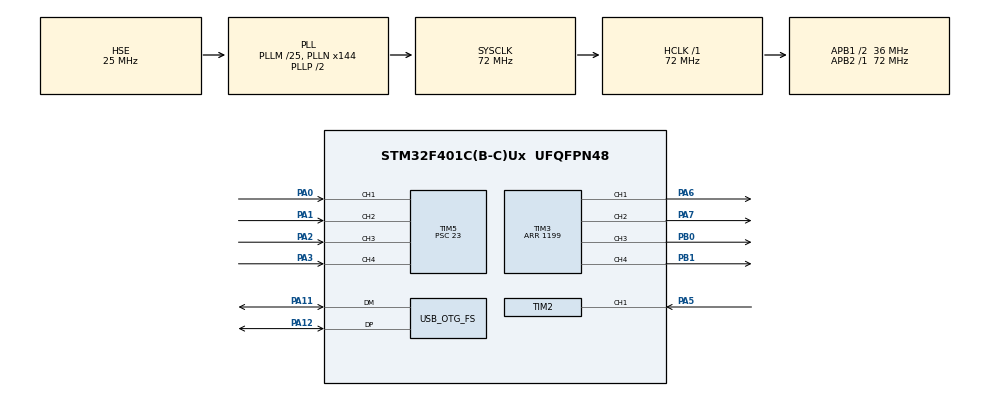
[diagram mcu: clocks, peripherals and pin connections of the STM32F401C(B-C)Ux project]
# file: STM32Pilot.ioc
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Dma.Request0=TIM2_CH1
Dma.Request1=TIM5_CH1
Dma.Request2=TIM5_CH2
Dma.Request3=TIM5_CH3/UP
Dma.Request4=TIM5_CH4/TRIG
Dma.TIM2_CH1.0.Direction=DMA_PERIPH_TO_MEMORY
Dma.TIM2_CH1.0.FIFOMode=DMA_FIFOMODE_DISABLE
Dma.TIM2_CH1.0.Instance=DMA1_Stream5
Dma.TIM2_CH1.0.MemDataAlignment=DMA_MDATAALIGN_WORD
Dma.TIM2_CH1.0.MemInc=DMA_MINC_ENABLE
Dma.TIM2_CH1.0.Mode=DMA_CIRCULAR
Dma.TIM2_CH1.0.PeriphDataAlignment=DMA_PDATAALIGN_WORD
Dma.TIM2_CH1.0.PeriphInc=DMA_PINC_DISABLE
Dma.TIM2_CH1.0.Priority=DMA_PRIORITY_LOW
Dma.TIM5_CH1.1.Direction=DMA_PERIPH_TO_MEMORY
Dma.TIM5_CH1.1.FIFOMode=DMA_FIFOMODE_DISABLE
Dma.TIM5_CH1.1.Instance=DMA1_Stream2
Dma.TIM5_CH1.1.MemDataAlignment=DMA_MDATAALIGN_WORD
Dma.TIM5_CH1.1.MemInc=DMA_MINC_ENABLE
Dma.TIM5_CH1.1.Mode=DMA_CIRCULAR
Dma.TIM5_CH1.1.PeriphDataAlignment=DMA_PDATAALIGN_WORD
Dma.TIM5_CH1.1.PeriphInc=DMA_PINC_DISABLE
Dma.TIM5_CH1.1.Priority=DMA_PRIORITY_LOW
Dma.TIM5_CH2.2.Direction=DMA_PERIPH_TO_MEMORY
Dma.TIM5_CH2.2.FIFOMode=DMA_FIFOMODE_DISABLE
Dma.TIM5_CH2.2.Instance=DMA1_Stream4
Dma.TIM5_CH2.2.MemDataAlignment=DMA_MDATAALIGN_WORD
Dma.TIM5_CH2.2.MemInc=DMA_MINC_ENABLE
Dma.TIM5_CH2.2.Mode=DMA_CIRCULAR
Dma.TIM5_CH2.2.PeriphDataAlignment=DMA_PDATAALIGN_WORD
Dma.TIM5_CH2.2.PeriphInc=DMA_PINC_DISABLE
Dma.TIM5_CH2.2.Priority=DMA_PRIORITY_LOW
Dma.TIM5_CH3/UP.3.Direction=DMA_PERIPH_TO_MEMORY
Dma.TIM5_CH3/UP.3.FIFOMode=DMA_FIFOMODE_DISABLE
Dma.TIM5_CH3/UP.3.Instance=DMA1_Stream0
Dma.TIM5_CH3/UP.3.MemDataAlignment=DMA_MDATAALIGN_WORD
Dma.TIM5_CH3/UP.3.MemInc=DMA_MINC_ENABLE
Dma.TIM5_CH3/UP.3.Mode=DMA_CIRCULAR
Dma.TIM5_CH3/UP.3.PeriphDataAlignment=DMA_PDATAALIGN_WORD
Dma.TIM5_CH3/UP.3.PeriphInc=DMA_PINC_DISABLE
Dma.TIM5_CH3/UP.3.Priority=DMA_PRIORITY_LOW
Dma.TIM5_CH4/TRIG.4.Direction=DMA_PERIPH_TO_MEMORY
Dma.TIM5_CH4/TRIG.4.FIFOMode=DMA_FIFOMODE_DISABLE
Dma.TIM5_CH4/TRIG.4.Instance=DMA1_Stream1
Dma.TIM5_CH4/TRIG.4.MemDataAlignment=DMA_MDATAALIGN_WORD
Dma.TIM5_CH4/TRIG.4.MemInc=DMA_MINC_ENABLE
Dma.TIM5_CH4/TRIG.4.Mode=DMA_CIRCULAR
Dma.TIM5_CH4/TRIG.4.PeriphDataAlignment=DMA_PDATAALIGN_WORD
Dma.TIM5_CH4/TRIG.4.PeriphInc=DMA_PINC_DISABLE
Dma.TIM5_CH4/TRIG.4.Priority=DMA_PRIORITY_LOW
Mcu.Family=STM32F4
Mcu.Name=STM32F401C(B-C)Ux
Mcu.Package=UFQFPN48
NVIC.DMA1_Stream0_IRQn=true\:0\:0\:false\:false\:true\:false\:true\:true
NVIC.DMA1_Stream1_IRQn=true\:0\:0\:false\:false\:true\:false\:true\:true
NVIC.DMA1_Stream2_IRQn=true\:0\:0\:false\:false\:true\:false\:true\:true
NVIC.DMA1_Stream4_IRQn=true\:0\:0\:false\:false\:true\:false\:true\:true
NVIC.DMA1_Stream5_IRQn=true\:0\:0\:false\:false\:true\:false\:true\:true
NVIC.OTG_FS_IRQn=true\:0\:0\:false\:false\:true\:false\:true\:true
NVIC.PriorityGroup=NVIC_PRIORITYGROUP_4
PA0-WKUP.Signal=S_TIM5_CH1
PA1.Signal=S_TIM5_CH2
PA11.Mode=Device_Only
PA11.Signal=USB_OTG_FS_DM
PA12.Mode=Device_Only
PA12.Signal=USB_OTG_FS_DP
PA2.Signal=S_TIM5_CH3
PA3.Signal=S_TIM5_CH4
PA5.Signal=S_TIM2_CH1_ETR
PA6.Signal=S_TIM3_CH1
PA7.Signal=S_TIM3_CH2
PB0.Signal=S_TIM3_CH3
PB1.Signal=S_TIM3_CH4
PC14-OSC32_IN.Mode=LSE-External-Oscillator
PC14-OSC32_IN.Signal=RCC_OSC32_IN
PC15-OSC32_OUT.Mode=LSE-External-Oscillator
PC15-OSC32_OUT.Signal=RCC_OSC32_OUT
PH0\ -\ OSC_IN.Mode=HSE-External-Oscillator
PH0\ -\ OSC_IN.Signal=RCC_OSC_IN
PH1\ -\ OSC_OUT.Mode=HSE-External-Oscillator
PH1\ -\ OSC_OUT.Signal=RCC_OSC_OUT
ProjectManager.HeapSize=0x200
ProjectManager.StackSize=0x400
ProjectManager.TargetToolchain=STM32CubeIDE
RCC.48MHZClocksFreq_Value=48000000
RCC.AHBFreq_Value=72000000
RCC.APB1CLKDivider=RCC_HCLK_DIV2
RCC.APB1Freq_Value=36000000
RCC.APB1TimFreq_Value=72000000
RCC.APB2Freq_Value=72000000
RCC.APB2TimFreq_Value=72000000
RCC.CortexFreq_Value=72000000
RCC.EnbaleCSS=true
RCC.HCLKFreq_Value=72000000
RCC.HSE_VALUE=25000000
RCC.HSI_VALUE=16000000
RCC.PLLM=25
RCC.PLLN=144
RCC.PLLQ=3
RCC.RCC_RTC_Clock_Source=RCC_RTCCLKSOURCE_LSE
RCC.RCC_RTC_Clock_SourceVirtual=RCC_RTCCLKSOURCE_LSE
RCC.SYSCLKFreq_VALUE=72000000
RCC.SYSCLKSource=RCC_SYSCLKSOURCE_PLLCLK
RCC.VCOOutputFreq_Value=144000000
SH.S_TIM2_CH1_ETR.0=TIM2_CH1,Input_Capture1_from_TI1
SH.S_TIM3_CH1.0=TIM3_CH1,PWM Generation1 CH1
SH.S_TIM3_CH2.0=TIM3_CH2,PWM Generation2 CH2
SH.S_TIM3_CH3.0=TIM3_CH3,PWM Generation3 CH3
SH.S_TIM3_CH4.0=TIM3_CH4,PWM Generation4 CH4
SH.S_TIM5_CH1.0=TIM5_CH1,Input_Capture1_from_TI1
SH.S_TIM5_CH2.0=TIM5_CH2,Input_Capture2_from_TI2
SH.S_TIM5_CH3.0=TIM5_CH3,Input_Capture3_from_TI3
SH.S_TIM5_CH4.0=TIM5_CH4,Input_Capture4_from_TI4
TIM2.Channel-Input_Capture1_from_TI1=TIM_CHANNEL_1
TIM2.ICPolarity_CH1=TIM_INPUTCHANNELPOLARITY_BOTHEDGE
TIM2.Prescaler=23
TIM3.Channel-PWM\ Generation1\ CH1=TIM_CHANNEL_1
TIM3.Channel-PWM\ Generation2\ CH2=TIM_CHANNEL_2
TIM3.Channel-PWM\ Generation3\ CH3=TIM_CHANNEL_3
TIM3.Channel-PWM\ Generation4\ CH4=TIM_CHANNEL_4
TIM3.Period=1199
TIM5.Channel-Input_Capture1_from_TI1=TIM_CHANNEL_1
TIM5.Channel-Input_Capture2_from_TI2=TIM_CHANNEL_2
TIM5.Channel-Input_Capture3_from_TI3=TIM_CHANNEL_3
TIM5.Channel-Input_Capture4_from_TI4=TIM_CHANNEL_4
TIM5.ICPolarity_CH1=TIM_INPUTCHANNELPOLARITY_BOTHEDGE
TIM5.ICPolarity_CH2=TIM_INPUTCHANNELPOLARITY_BOTHEDGE
TIM5.ICPolarity_CH3=TIM_INPUTCHANNELPOLARITY_BOTHEDGE
TIM5.ICPolarity_CH4=TIM_INPUTCHANNELPOLARITY_BOTHEDGE
TIM5.Prescaler=23
USB_DEVICE.CLASS_NAME_FS=CDC
USB_DEVICE.CONFIGURATION_STRING_CDC_FS=STM32P Config
USB_DEVICE.INTERFACE_STRING_CDC_FS=STM32P Interface
USB_DEVICE.MANUFACTURER_STRING=LEET PWNZ
USB_DEVICE.PID_CDC_FS=1
USB_DEVICE.PRODUCT_STRING_CDC_FS=STM32 Pilot
USB_DEVICE.VID=9999
USB_DEVICE.VirtualMode=Cdc
USB_DEVICE.VirtualModeFS=Cdc_FS
USB_OTG_FS.VirtualMode=Device_Only
VP_RTC_VS_RTC_Activate.Mode=RTC_Enabled
VP_USB_DEVICE_VS_USB_DEVICE_CDC_FS.Mode=CDC_FS
board=custom

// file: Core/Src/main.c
/* USER CODE BEGIN Header */
/* USER CODE END Header */
#include "main.h"
#include "usb_device.h"

/* USER CODE BEGIN Includes */
#include "C2CPP.h"
/* USER CODE END Includes */

RTC_HandleTypeDef hrtc;

TIM_HandleTypeDef htim2;
TIM_HandleTypeDef htim3;
TIM_HandleTypeDef htim5;
DMA_HandleTypeDef hdma_tim2_ch1;
DMA_HandleTypeDef hdma_tim5_ch1;
DMA_HandleTypeDef hdma_tim5_ch2;
DMA_HandleTypeDef hdma_tim5_ch3_up;
DMA_HandleTypeDef hdma_tim5_ch4_trig;

void SystemClock_Config(void);
static void MX_GPIO_Init(void);
static void MX_DMA_Init(void);
static void MX_RTC_Init(void);
static void MX_TIM2_Init(void);
static void MX_TIM5_Init(void);
static void MX_TIM3_Init(void);

int main(void)
{

  /* MCU Configuration--------------------------------------------------------*/

  /* Reset of all peripherals, Initializes the Flash interface and the Systick. */
  HAL_Init();

  /* Configure the system clock */
  SystemClock_Config();

  /* Initialize all configured peripherals */
  MX_GPIO_Init();
  MX_DMA_Init();
  MX_RTC_Init();
  MX_TIM2_Init();
  MX_TIM5_Init();
  MX_TIM3_Init();
  MX_USB_DEVICE_Init();

  /* Infinite loop */

    /* USER CODE BEGIN 3 */
  C2CPPStartup(&htim2, &htim5, &htim3);
  while(1){
	  C2CPPLoop();
  }
  /* USER CODE END 3 */
}

void SystemClock_Config(void)
{
  RCC_OscInitTypeDef RCC_OscInitStruct = {0};
  RCC_ClkInitTypeDef RCC_ClkInitStruct = {0};

  /** Configure the main internal regulator output voltage
  */
  __HAL_RCC_PWR_CLK_ENABLE();
  __HAL_PWR_VOLTAGESCALING_CONFIG(PWR_REGULATOR_VOLTAGE_SCALE2);

  /** Initializes the RCC Oscillators according to the specified parameters
  * in the RCC_OscInitTypeDef structure.
  */
  RCC_OscInitStruct.OscillatorType = RCC_OSCILLATORTYPE_LSI|RCC_OSCILLATORTYPE_HSE
                              |RCC_OSCILLATORTYPE_LSE;
  RCC_OscInitStruct.HSEState = RCC_HSE_ON;
  RCC_OscInitStruct.LSEState = RCC_LSE_ON;
  RCC_OscInitStruct.LSIState = RCC_LSI_ON;
  RCC_OscInitStruct.PLL.PLLState = RCC_PLL_ON;
  RCC_OscInitStruct.PLL.PLLSource = RCC_PLLSOURCE_HSE;
  RCC_OscInitStruct.PLL.PLLM = 25;
  RCC_OscInitStruct.PLL.PLLN = 144;
  RCC_OscInitStruct.PLL.PLLP = RCC_PLLP_DIV2;
  RCC_OscInitStruct.PLL.PLLQ = 3;
  if (HAL_RCC_OscConfig(&RCC_OscInitStruct) != HAL_OK)
  {
    Error_Handler();
  }

  /** Initializes the CPU, AHB and APB buses clocks
  */
  RCC_ClkInitStruct.ClockType = RCC_CLOCKTYPE_HCLK|RCC_CLOCKTYPE_SYSCLK
                              |RCC_CLOCKTYPE_PCLK1|RCC_CLOCKTYPE_PCLK2;
  RCC_ClkInitStruct.SYSCLKSource = RCC_SYSCLKSOURCE_PLLCLK;
  RCC_ClkInitStruct.AHBCLKDivider = RCC_SYSCLK_DIV1;
  RCC_ClkInitStruct.APB1CLKDivider = RCC_HCLK_DIV2;
  RCC_ClkInitStruct.APB2CLKDivider = RCC_HCLK_DIV1;

  if (HAL_RCC_ClockConfig(&RCC_ClkInitStruct, FLASH_LATENCY_2) != HAL_OK)
  {
    Error_Handler();
  }

  /** Enables the Clock Security System
  */
  HAL_RCC_EnableCSS();
}

static void MX_RTC_Init(void)
{

  /** Initialize RTC Only
  */
  hrtc.Instance = RTC;
  hrtc.Init.HourFormat = RTC_HOURFORMAT_24;
  hrtc.Init.AsynchPrediv = 127;
  hrtc.Init.SynchPrediv = 255;
  hrtc.Init.OutPut = RTC_OUTPUT_DISABLE;
  hrtc.Init.OutPutPolarity = RTC_OUTPUT_POLARITY_HIGH;
  hrtc.Init.OutPutType = RTC_OUTPUT_TYPE_OPENDRAIN;
  if (HAL_RTC_Init(&hrtc) != HAL_OK)
  {
    Error_Handler();
  }

}

static void MX_TIM2_Init(void)
{

  TIM_MasterConfigTypeDef sMasterConfig = {0};
  TIM_IC_InitTypeDef sConfigIC = {0};

  htim2.Instance = TIM2;
  htim2.Init.Prescaler = 23;
  htim2.Init.CounterMode = TIM_COUNTERMODE_UP;
  htim2.Init.Period = 4294967295;
  htim2.Init.ClockDivision = TIM_CLOCKDIVISION_DIV1;
  htim2.Init.AutoReloadPreload = TIM_AUTORELOAD_PRELOAD_DISABLE;
  if (HAL_TIM_IC_Init(&htim2) != HAL_OK)
  {
    Error_Handler();
  }
  sMasterConfig.MasterOutputTrigger = TIM_TRGO_RESET;
  sMasterConfig.MasterSlaveMode = TIM_MASTERSLAVEMODE_DISABLE;
  if (HAL_TIMEx_MasterConfigSynchronization(&htim2, &sMasterConfig) != HAL_OK)
  {
    Error_Handler();
  }
  sConfigIC.ICPolarity = TIM_INPUTCHANNELPOLARITY_BOTHEDGE;
  sConfigIC.ICSelection = TIM_ICSELECTION_DIRECTTI;
  sConfigIC.ICPrescaler = TIM_ICPSC_DIV1;
  sConfigIC.ICFilter = 0;
  if (HAL_TIM_IC_ConfigChannel(&htim2, &sConfigIC, TIM_CHANNEL_1) != HAL_OK)
  {
    Error_Handler();
  }

}

static void MX_TIM3_Init(void)
{

  TIM_MasterConfigTypeDef sMasterConfig = {0};
  TIM_OC_InitTypeDef sConfigOC = {0};

  htim3.Instance = TIM3;
  htim3.Init.Prescaler = 0;
  htim3.Init.CounterMode = TIM_COUNTERMODE_UP;
  htim3.Init.Period = 1199;
  htim3.Init.ClockDivision = TIM_CLOCKDIVISION_DIV1;
  htim3.Init.AutoReloadPreload = TIM_AUTORELOAD_PRELOAD_DISABLE;
  if (HAL_TIM_PWM_Init(&htim3) != HAL_OK)
  {
    Error_Handler();
  }
  sMasterConfig.MasterOutputTrigger = TIM_TRGO_RESET;
  sMasterConfig.MasterSlaveMode = TIM_MASTERSLAVEMODE_DISABLE;
  if (HAL_TIMEx_MasterConfigSynchronization(&htim3, &sMasterConfig) != HAL_OK)
  {
    Error_Handler();
  }
  sConfigOC.OCMode = TIM_OCMODE_PWM1;
  sConfigOC.Pulse = 0;
  sConfigOC.OCPolarity = TIM_OCPOLARITY_HIGH;
  sConfigOC.OCFastMode = TIM_OCFAST_DISABLE;
  if (HAL_TIM_PWM_ConfigChannel(&htim3, &sConfigOC, TIM_CHANNEL_1) != HAL_OK)
  {
    Error_Handler();
  }
  if (HAL_TIM_PWM_ConfigChannel(&htim3, &sConfigOC, TIM_CHANNEL_2) != HAL_OK)
  {
    Error_Handler();
  }
  if (HAL_TIM_PWM_ConfigChannel(&htim3, &sConfigOC, TIM_CHANNEL_3) != HAL_OK)
  {
    Error_Handler();
  }
  if (HAL_TIM_PWM_ConfigChannel(&htim3, &sConfigOC, TIM_CHANNEL_4) != HAL_OK)
  {
    Error_Handler();
  }
  HAL_TIM_MspPostInit(&htim3);

}

static void MX_TIM5_Init(void)
{

  TIM_MasterConfigTypeDef sMasterConfig = {0};
  TIM_IC_InitTypeDef sConfigIC = {0};

  htim5.Instance = TIM5;
  htim5.Init.Prescaler = 23;
  htim5.Init.CounterMode = TIM_COUNTERMODE_UP;
  htim5.Init.Period = 4294967295;
  htim5.Init.ClockDivision = TIM_CLOCKDIVISION_DIV1;
  htim5.Init.AutoReloadPreload = TIM_AUTORELOAD_PRELOAD_DISABLE;
  if (HAL_TIM_IC_Init(&htim5) != HAL_OK)
  {
    Error_Handler();
  }
  sMasterConfig.MasterOutputTrigger = TIM_TRGO_RESET;
  sMasterConfig.MasterSlaveMode = TIM_MASTERSLAVEMODE_DISABLE;
  if (HAL_TIMEx_MasterConfigSynchronization(&htim5, &sMasterConfig) != HAL_OK)
  {
    Error_Handler();
  }
  sConfigIC.ICPolarity = TIM_INPUTCHANNELPOLARITY_BOTHEDGE;
  sConfigIC.ICSelection = TIM_ICSELECTION_DIRECTTI;
  sConfigIC.ICPrescaler = TIM_ICPSC_DIV1;
  sConfigIC.ICFilter = 0;
  if (HAL_TIM_IC_ConfigChannel(&htim5, &sConfigIC, TIM_CHANNEL_1) != HAL_OK)
  {
    Error_Handler();
  }
  if (HAL_TIM_IC_ConfigChannel(&htim5, &sConfigIC, TIM_CHANNEL_2) != HAL_OK)
  {
    Error_Handler();
  }
  if (HAL_TIM_IC_ConfigChannel(&htim5, &sConfigIC, TIM_CHANNEL_3) != HAL_OK)
  {
    Error_Handler();
  }
  if (HAL_TIM_IC_ConfigChannel(&htim5, &sConfigIC, TIM_CHANNEL_4) != HAL_OK)
  {
    Error_Handler();
  }

}

static void MX_DMA_Init(void)
{

  /* DMA controller clock enable */
  __HAL_RCC_DMA1_CLK_ENABLE();

  /* DMA interrupt init */
  /* DMA1_Stream0_IRQn interrupt configuration */
  HAL_NVIC_SetPriority(DMA1_Stream0_IRQn, 0, 0);
  HAL_NVIC_EnableIRQ(DMA1_Stream0_IRQn);
  /* DMA1_Stream1_IRQn interrupt configuration */
  HAL_NVIC_SetPriority(DMA1_Stream1_IRQn, 0, 0);
  HAL_NVIC_EnableIRQ(DMA1_Stream1_IRQn);
  /* DMA1_Stream2_IRQn interrupt configuration */
  HAL_NVIC_SetPriority(DMA1_Stream2_IRQn, 0, 0);
  HAL_NVIC_EnableIRQ(DMA1_Stream2_IRQn);
  /* DMA1_Stream4_IRQn interrupt configuration */
  HAL_NVIC_SetPriority(DMA1_Stream4_IRQn, 0, 0);
  HAL_NVIC_EnableIRQ(DMA1_Stream4_IRQn);
  /* DMA1_Stream5_IRQn interrupt configuration */
  HAL_NVIC_SetPriority(DMA1_Stream5_IRQn, 0, 0);
  HAL_NVIC_EnableIRQ(DMA1_Stream5_IRQn);

}

static void MX_GPIO_Init(void)
{

  /* GPIO Ports Clock Enable */
  __HAL_RCC_GPIOC_CLK_ENABLE();
  __HAL_RCC_GPIOH_CLK_ENABLE();
  __HAL_RCC_GPIOA_CLK_ENABLE();
  __HAL_RCC_GPIOB_CLK_ENABLE();

}

void Error_Handler(void)
{
}
